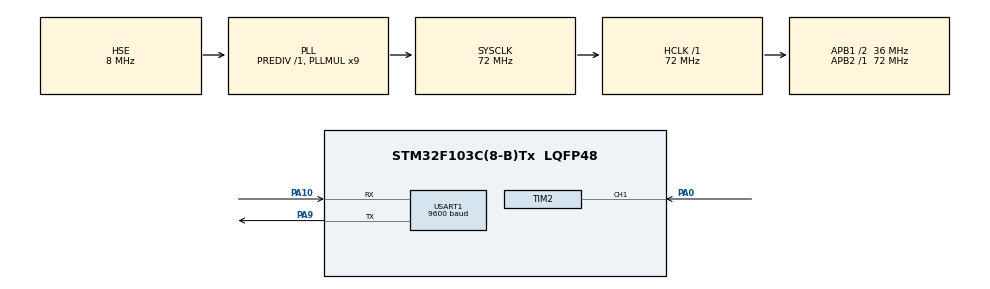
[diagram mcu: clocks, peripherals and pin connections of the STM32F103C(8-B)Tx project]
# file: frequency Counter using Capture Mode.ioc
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Mcu.Family=STM32F1
Mcu.Name=STM32F103C(8-B)Tx
Mcu.Package=LQFP48
NVIC.PriorityGroup=NVIC_PRIORITYGROUP_4
NVIC.TIM2_IRQn=true\:0\:0\:false\:false\:true\:true\:true
PA0-WKUP.Signal=S_TIM2_CH1_ETR
PA10.Mode=Asynchronous
PA10.Signal=USART1_RX
PA13.Mode=Serial_Wire
PA13.Signal=SYS_JTMS-SWDIO
PA14.Mode=Serial_Wire
PA14.Signal=SYS_JTCK-SWCLK
PA9.Mode=Asynchronous
PA9.Signal=USART1_TX
PD0-OSC_IN.Mode=HSE-External-Oscillator
PD0-OSC_IN.Signal=RCC_OSC_IN
PD1-OSC_OUT.Mode=HSE-External-Oscillator
PD1-OSC_OUT.Signal=RCC_OSC_OUT
ProjectManager.HeapSize=0x200
ProjectManager.StackSize=0x400
ProjectManager.TargetToolchain=STM32CubeIDE
RCC.AHBFreq_Value=72000000
RCC.APB1CLKDivider=RCC_HCLK_DIV2
RCC.APB1Freq_Value=36000000
RCC.APB1TimFreq_Value=72000000
RCC.APB2Freq_Value=72000000
RCC.APB2TimFreq_Value=72000000
RCC.HCLKFreq_Value=72000000
RCC.PLLMUL=RCC_PLL_MUL9
RCC.PLLSourceVirtual=RCC_PLLSOURCE_HSE
RCC.SYSCLKFreq_VALUE=72000000
RCC.SYSCLKSource=RCC_SYSCLKSOURCE_PLLCLK
RCC.USBFreq_Value=72000000
SH.S_TIM2_CH1_ETR.0=TIM2_CH1,Input_Capture1_from_TI1
TIM2.AutoReloadPreload=TIM_AUTORELOAD_PRELOAD_ENABLE
TIM2.Channel-Input_Capture1_from_TI1=TIM_CHANNEL_1
USART1.BaudRate=9600
USART1.VirtualMode=VM_ASYNC
VP_TIM2_VS_ClockSourceINT.Mode=Internal
board=custom

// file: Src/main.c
/* USER CODE BEGIN Header */
/**
  ******************************************************************************
  * @file           : main.c
  * @brief          : Main program body
  ******************************************************************************
  * @attention
  *
  * Copyright (c) 2022 STMicroelectronics.
  * All rights reserved.
  *
  * This software is licensed under terms that can be found in the LICENSE file
  * in the root directory of this software component.
  * If no LICENSE file comes with this software, it is provided AS-IS.
  *
  ******************************************************************************
  */
/* USER CODE END Header */
#include "main.h"

/* USER CODE BEGIN PD */
#define internal_clock 72000000//indicates unsigned long
#define clock_count 65535

/* USER CODE END PD */

TIM_HandleTypeDef htim2;

UART_HandleTypeDef huart1;

/* USER CODE BEGIN PV */
uint8_t msg[40]={'\n'};
uint8_t count_1 = 0;
uint8_t count_2 = 0;
uint8_t first_count = 1;
uint64_t wave_freq = 0;
uint8_t  num_ovf = 0;
/* USER CODE END PV */

void SystemClock_Config(void);
static void MX_GPIO_Init(void);
static void MX_TIM2_Init(void);
static void MX_USART1_UART_Init(void);

int main(void)
{

  /* MCU Configuration--------------------------------------------------------*/

  /* Reset of all peripherals, Initializes the Flash interface and the Systick. */
  HAL_Init();

  /* Configure the system clock */
  SystemClock_Config();

  /* Initialize all configured peripherals */
  MX_GPIO_Init();
  MX_TIM2_Init();
  MX_USART1_UART_Init();
  /* USER CODE BEGIN 2 */
  HAL_TIM_Base_Start_IT(&htim2);
  HAL_TIM_IC_Start_IT(&htim2, TIM_CHANNEL_1);
  /* USER CODE END 2 */

  /* Infinite loop */
  while (1)
  {

  }
}

void SystemClock_Config(void)
{
  RCC_OscInitTypeDef RCC_OscInitStruct = {0};
  RCC_ClkInitTypeDef RCC_ClkInitStruct = {0};

  /** Initializes the RCC Oscillators according to the specified parameters
  * in the RCC_OscInitTypeDef structure.
  */
  RCC_OscInitStruct.OscillatorType = RCC_OSCILLATORTYPE_HSE;
  RCC_OscInitStruct.HSEState = RCC_HSE_ON;
  RCC_OscInitStruct.HSEPredivValue = RCC_HSE_PREDIV_DIV1;
  RCC_OscInitStruct.HSIState = RCC_HSI_ON;
  RCC_OscInitStruct.PLL.PLLState = RCC_PLL_ON;
  RCC_OscInitStruct.PLL.PLLSource = RCC_PLLSOURCE_HSE;
  RCC_OscInitStruct.PLL.PLLMUL = RCC_PLL_MUL9;
  if (HAL_RCC_OscConfig(&RCC_OscInitStruct) != HAL_OK)
  {
    Error_Handler();
  }
  /** Initializes the CPU, AHB and APB buses clocks
  */
  RCC_ClkInitStruct.ClockType = RCC_CLOCKTYPE_HCLK|RCC_CLOCKTYPE_SYSCLK
                              |RCC_CLOCKTYPE_PCLK1|RCC_CLOCKTYPE_PCLK2;
  RCC_ClkInitStruct.SYSCLKSource = RCC_SYSCLKSOURCE_PLLCLK;
  RCC_ClkInitStruct.AHBCLKDivider = RCC_SYSCLK_DIV1;
  RCC_ClkInitStruct.APB1CLKDivider = RCC_HCLK_DIV2;
  RCC_ClkInitStruct.APB2CLKDivider = RCC_HCLK_DIV1;

  if (HAL_RCC_ClockConfig(&RCC_ClkInitStruct, FLASH_LATENCY_2) != HAL_OK)
  {
    Error_Handler();
  }
}

static void MX_TIM2_Init(void)
{

  TIM_ClockConfigTypeDef sClockSourceConfig = {0};
  TIM_MasterConfigTypeDef sMasterConfig = {0};
  TIM_IC_InitTypeDef sConfigIC = {0};

  htim2.Instance = TIM2;
  htim2.Init.Prescaler = 0;
  htim2.Init.CounterMode = TIM_COUNTERMODE_UP;
  htim2.Init.Period = 65535;
  htim2.Init.ClockDivision = TIM_CLOCKDIVISION_DIV1;
  htim2.Init.AutoReloadPreload = TIM_AUTORELOAD_PRELOAD_ENABLE;
  if (HAL_TIM_Base_Init(&htim2) != HAL_OK)
  {
    Error_Handler();
  }
  sClockSourceConfig.ClockSource = TIM_CLOCKSOURCE_INTERNAL;
  if (HAL_TIM_ConfigClockSource(&htim2, &sClockSourceConfig) != HAL_OK)
  {
    Error_Handler();
  }
  if (HAL_TIM_IC_Init(&htim2) != HAL_OK)
  {
    Error_Handler();
  }
  sMasterConfig.MasterOutputTrigger = TIM_TRGO_RESET;
  sMasterConfig.MasterSlaveMode = TIM_MASTERSLAVEMODE_DISABLE;
  if (HAL_TIMEx_MasterConfigSynchronization(&htim2, &sMasterConfig) != HAL_OK)
  {
    Error_Handler();
  }
  sConfigIC.ICPolarity = TIM_INPUTCHANNELPOLARITY_RISING;
  sConfigIC.ICSelection = TIM_ICSELECTION_DIRECTTI;
  sConfigIC.ICPrescaler = TIM_ICPSC_DIV1;
  sConfigIC.ICFilter = 0;
  if (HAL_TIM_IC_ConfigChannel(&htim2, &sConfigIC, TIM_CHANNEL_1) != HAL_OK)
  {
    Error_Handler();
  }

}

static void MX_USART1_UART_Init(void)
{

  huart1.Instance = USART1;
  huart1.Init.BaudRate = 9600;
  huart1.Init.WordLength = UART_WORDLENGTH_8B;
  huart1.Init.StopBits = UART_STOPBITS_1;
  huart1.Init.Parity = UART_PARITY_NONE;
  huart1.Init.Mode = UART_MODE_TX_RX;
  huart1.Init.HwFlowCtl = UART_HWCONTROL_NONE;
  huart1.Init.OverSampling = UART_OVERSAMPLING_16;
  if (HAL_UART_Init(&huart1) != HAL_OK)
  {
    Error_Handler();
  }

}

static void MX_GPIO_Init(void)
{

  /* GPIO Ports Clock Enable */
  __HAL_RCC_GPIOD_CLK_ENABLE();
  __HAL_RCC_GPIOA_CLK_ENABLE();

}

/* USER CODE BEGIN 4 */
void HAL_TIM_IC_CaptureCallback(TIM_HandleTypeDef* htim)
{
	if(first_count){
		count_1 = TIM2->CCR1;
		first_count = 0;
		num_ovf = 0;
	}
	else
	{
		count_2 = TIM2->CCR1;
		wave_freq = (uint32_t)internal_clock/(count_2 + (clock_count*num_ovf)- count_1);
        if(wave_freq != 0)
        {
        sprintf(msg, "Frequency = %lu Hz\n\r", wave_freq);
        HAL_UART_Transmit(&huart1, msg, sizeof(msg), 100);
		first_count = 1;
        }

	}

}

void HAL_TIM_PeriodElapsedCallback(TIM_HandleTypeDef* htim)
{
	num_ovf++;
}
/* USER CODE END 4 */

void Error_Handler(void)
{
  __disable_irq();
  while (1)
  {
  }
}
